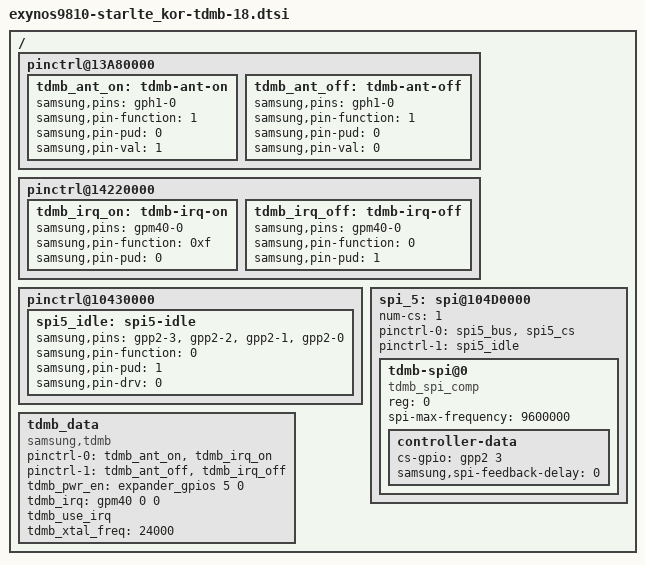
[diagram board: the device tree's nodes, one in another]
 /* Copyright (c) 2012-2014, The Linux Foundation. All rights reserved.
  *
  * This program is free software; you can redistribute it and/or modify
  * it under the terms of the GNU General Public License version 2 and
  * only version 2 as published by the Free Software Foundation.
  *
  * This program is distributed in the hope that it will be useful,
  * but WITHOUT ANY WARRANTY; without even the implied warranty of
  * MERCHANTABILITY or FITNESS FOR A PARTICULAR PURPOSE.  See the
  * GNU General Public License for more details.
  */

/{
	pinctrl@13A80000 {
		tdmb_ant_on: tdmb-ant-on {
			samsung,pins = "gph1-0";
			samsung,pin-function = <1>;
			samsung,pin-pud = <0>;
			samsung,pin-val = <1>;
		};
		tdmb_ant_off: tdmb-ant-off {
			samsung,pins = "gph1-0";
			samsung,pin-function = <1>;
			samsung,pin-pud = <0>;
			samsung,pin-val = <0>;
		};
	};

	pinctrl@14220000 {
		tdmb_irq_on: tdmb-irq-on {
			samsung,pins = "gpm40-0";
			samsung,pin-function = <0xf>; /* EXT_INT71[1] */
			samsung,pin-pud = <0>;	/* PULL NONE */
		};
		tdmb_irq_off: tdmb-irq-off {
			samsung,pins = "gpm40-0";
			samsung,pin-function = <0>; /* INPUT */
			samsung,pin-pud = <1>;	/* PULL DOWN */
		};
	};

	pinctrl@10430000 {
		spi5_idle: spi5-idle {
			samsung,pins = "gpp2-3", "gpp2-2", "gpp2-1", "gpp2-0";
			samsung,pin-function = <0>;
			samsung,pin-pud = <1>;
			samsung,pin-drv = <0>;
		};
	};

	spi_5: spi@104D0000 {
		#address-cells = <1>;
		#size-cells = <0>;
		num-cs = <1>;
/*
 *		dma-mode;
 *		dmas = <&pdma0 9 1 &pdma0 8 1>;
 *		dma-names = "tx", "rx";
 */
		status = "ok";

		pinctrl-names = "default", "idle";
		pinctrl-0 = <&spi5_bus &spi5_cs>;
		pinctrl-1 = <&spi5_idle>;

		tdmb-spi@0 {
			compatible = "tdmb_spi_comp";
			reg = <0>;
			spi-max-frequency = <9600000>;
			controller-data {
				cs-gpio = <&gpp2 3 0>;
				samsung,spi-feedback-delay = <0>;
			};
		};
	};

	tdmb_data {
		compatible = "samsung,tdmb";
		pinctrl-names = "tdmb_on", "tdmb_off";
		pinctrl-0 = <&tdmb_ant_on &tdmb_irq_on>;
		pinctrl-1 = <&tdmb_ant_off &tdmb_irq_off>;
		tdmb_pwr_en = <&expander_gpios 5 0>;
		tdmb_irq = <&gpm40 0 0>;
		tdmb_use_irq;
		tdmb_xtal_freq = <24000>;
	};

};
